# STM8S105C6 register map
Vendor: STMicroelectronics; Series: STM8S/STM8AF, medium density; File version: 1.0
Mainstream Access line 8-bit MCU with 32 Kbytes Flash, 16 MHz CPU, integrated EEPROM
CPU: other r1p0, big endian, no MPU, no FPU
Registers are 8-bit, read-write, reset 0x0 unless marked. A register's access mark holds for its fields unless they carry their own. Offsets are from the block's base; lines under a group give offsets from that group; [hi:lo] are bit positions; {n}, {i} and the like mark numbered series; 'fields as' and 'values as' point back to an identical list; <NAME> marks a mode.

## Memory map
0x00004800 OPT blocks up to offset 0x80
0x00005000 PORTA size 0x5
0x00005005 PORTB size 0x5
0x0000500A PORTC size 0x5
0x0000500F PORTD size 0x5
0x00005014 PORTE size 0x5
0x00005019 PORTF size 0x5
0x0000501E PORTG size 0x5
0x00005023 PORTH size 0x5
0x00005028 PORTI size 0x5
0x0000505A FLASH blocks up to offset 0xB
0x000050A0 ITC_EXTI size 0x2
0x000050B3 RST size 0x1
0x000050C0 CLK blocks up to offset 0xE
0x000050D1 WWDG size 0x2
0x000050E0 IWDG size 0x3
0x000050F0 AWU size 0x3
0x000050F3 BEEP size 0x1
0x00005200 SPI size 0x8
0x00005210 I2C blocks up to offset 0xF
0x00005240 UART2 blocks up to offset 0xC
0x00005250 TIM1 size 0x20
0x00005300 TIM2 size 0x15
0x00005320 TIM3 size 0x11
0x00005340 TIM4 size 0x7
0x000053E0 ADC1 blocks up to offset 0x30
0x00007F00 CPU blocks up to offset 0x61
0x00007F70 ITC_SPR size 0x8
0x00007F80 SWIM size 0x1
0x00007F90 DM size 0xB

## Interrupts
1 AWU_AWU (AWU) — AWU_AWU interrupt
2 CLK_CSS_SWITCH (CLK) — CLK_CSS_SWITCH interrupt
10 SPI_CRCERR_MODF_OVR_RXNE_TXE_WKUP (SPI) — SPI_CRCERR_MODF_OVR_RXNE_TXE_WKUP interrupt
11 TIM1_OVR_BIF_OVR_TIF_OVR_UIF (TIM1) — TIM1_OVR_BIF_OVR_TIF_OVR_UIF interrupt
12 TIM1_CC1IF_CC2IF_CC3IF_CC4IF_COMIF (TIM1) — TIM1_CC1IF_CC2IF_CC3IF_CC4IF_COMIF interrupt
13 TIM2_OVR_UIF (TIM2) — TIM2_OVR_UIF interrupt
14 TIM2_CC1IF_CC2IF_CC3IF_TIF (TIM2) — TIM2_CC1IF_CC2IF_CC3IF_TIF interrupt
15 TIM3_OVR_UIF (TIM3) — TIM3_OVR_UIF interrupt
16 TIM3_CC1IF_CC2IF_CC3IF_TIF (TIM3) — TIM3_CC1IF_CC2IF_CC3IF_TIF interrupt
19 I2C_ADD10_ADDR_AF_ARLO_BERR_BTF_OVR_RXNE_SB_STOPF_TXE_WUFH (I2C) — I2C_ADD10_ADDR_AF_ARLO_BERR_BTF_OVR_RXNE_SB_STOPF_TXE_WUFH interrupt
20 UART2_TC_TXE (UART2) — UART2_TC_TXE interrupt
21 UART2_IDLE_LBDF_OR_PE_RXNE (UART2) — UART2_IDLE_LBDF_OR_PE_RXNE interrupt
22 ADC1_AWDG_AWS0_AWS1_AWS2_AWS3_AWS4_AWS5_AWS6_AWS7_AWS8_AWS9_EOC (ADC1) — ADC1_AWDG_AWS0_AWS1_AWS2_AWS3_AWS4_AWS5_AWS6_AWS7_AWS8_AWS9_EOC interrupt
23 TIM4_OVR_UIF (TIM4) — TIM4_OVR_UIF interrupt
24 FLASH_EOP_WR_PG_DIS (FLASH) — FLASH_EOP_WR_PG_DIS interrupt

## ADC1
Base 0x000053E0
{0x0+2i} DB{i}RH (i=0..9) — ADC data buffer registers
  [7:0] DBH
{0x1+2i} DB{i}RL (i=0..9) — ADC data buffer registers
  [7:0] DL
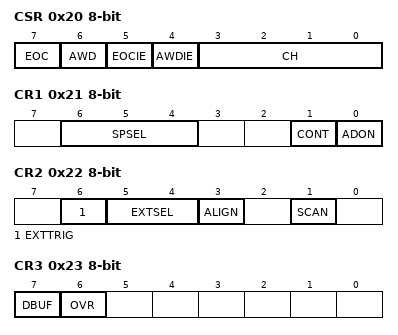
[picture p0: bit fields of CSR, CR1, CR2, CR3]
0x20 CSR — ADC control/status register
  [7] EOC, [6] AWD, [5] EOCIE, [4] AWDIE, [3:0] CH
0x21 CR1 — ADC configuration register 1
  [6:4] SPSEL, [1] CONT, [0] ADON
0x22 CR2 — ADC configuration register 2
  [6] EXTTRIG, [5:4] EXTSEL, [3] ALIGN, [1] SCAN
0x23 CR3 — ADC configuration register 3
  [7] DBUF, [6] OVR
0x24 DRH — ADC data register high
  [7:0] DH
0x25 DRL — ADC data register low
  [7:0] DL
0x26 TDRH — ADC Schmitt trigger disable register high
  [7:0] TD
0x27 TDRL — ADC Schmitt trigger disable register low
  [7:0] TL
0x28 HTRH reset 0x3 — ADC high threshold register high
  [7:0] HT
0x29 HTRL reset 0xFF — ADC high threshold register low
  [1:0] HT
0x2A LTRH — ADC low threshold register high
  [7:0] LT
0x2B LTRL — ADC low threshold register low
  [1:0] LT
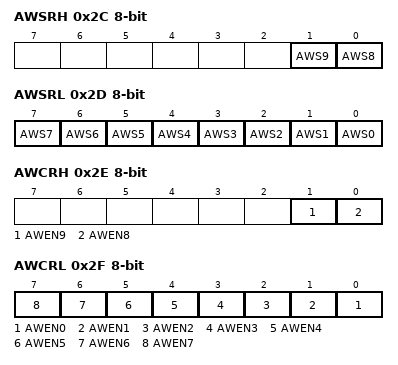
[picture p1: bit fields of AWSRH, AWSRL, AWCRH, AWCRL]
0x2C AWSRH — ADC analog watchdog status register high
  [1] AWS9, [0] AWS8
0x2D AWSRL — ADC analog watchdog status register low
  [n] AWS{n} (n=0..7)
0x2E AWCRH — ADC analog watchdog control register high
  [1] AWEN9, [0] AWEN8
0x2F AWCRL — ADC analog watchdog control register low
  [n] AWEN{n} (n=0..7)

## AWU
Base 0x000050F0
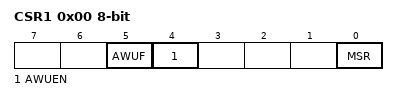
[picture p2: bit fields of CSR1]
0x00 CSR1 — AWU control/status register 1
  [5] AWUF, [4] AWUEN, [0] MSR
0x01 APR reset 0x3F — AWU asynchronous prescaler buffer register
  [5:0] APR
0x02 TBR — AWU timebase selection register
  [3:0] AWUTB
